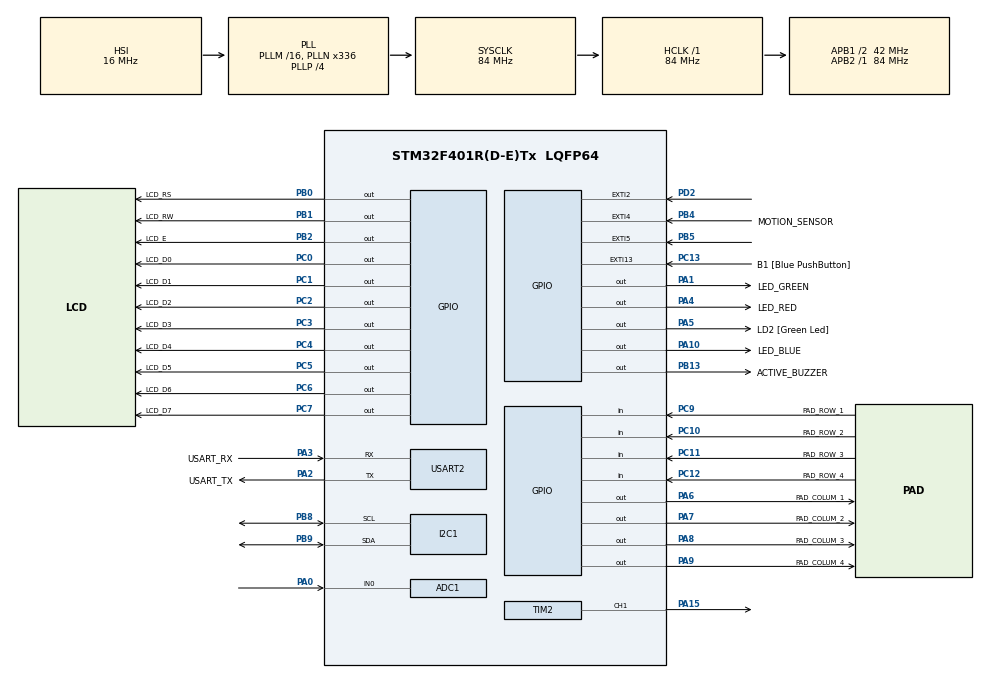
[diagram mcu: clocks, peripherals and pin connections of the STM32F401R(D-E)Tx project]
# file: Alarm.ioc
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ADC1.Channel-0\#ChannelRegularConversion=ADC_CHANNEL_0
ADC1.ClockPrescaler=ADC_CLOCK_SYNC_PCLK_DIV8
ADC1.NbrOfConversionFlag=1
ADC1.Rank-0\#ChannelRegularConversion=1
ADC1.SamplingTime-0\#ChannelRegularConversion=ADC_SAMPLETIME_480CYCLES
ADC1.master=1
Mcu.Family=STM32F4
Mcu.Name=STM32F401R(D-E)Tx
Mcu.Package=LQFP64
NVIC.EXTI2_IRQn=true\:2\:0\:true\:false\:true\:true
NVIC.EXTI4_IRQn=true\:2\:0\:true\:false\:true\:true
NVIC.EXTI9_5_IRQn=true\:2\:0\:true\:false\:true\:true
NVIC.PriorityGroup=NVIC_PRIORITYGROUP_4
NVIC.TIM1_BRK_TIM9_IRQn=true\:0\:0\:false\:false\:true\:true
NVIC.TIM1_TRG_COM_TIM11_IRQn=true\:0\:0\:false\:false\:true\:true
NVIC.TIM1_UP_TIM10_IRQn=true\:0\:0\:false\:false\:true\:true
PA0-WKUP.Signal=ADCx_IN0
PA1.GPIO_Label=LED_GREEN
PA1.GPIO_ModeDefaultOutputPP=GPIO_MODE_OUTPUT_OD
PA1.Signal=GPIO_Output
PA10.GPIO_Label=LED_BLUE
PA10.GPIO_ModeDefaultOutputPP=GPIO_MODE_OUTPUT_OD
PA10.Signal=GPIO_Output
PA13.GPIO_Label=TMS
PA13.Mode=Serial_Wire
PA13.Signal=SYS_JTMS-SWDIO
PA14.GPIO_Label=TCK
PA14.Mode=Serial_Wire
PA14.Signal=SYS_JTCK-SWCLK
PA15.Signal=S_TIM2_CH1_ETR
PA2.GPIO_Label=USART_TX
PA2.GPIO_Mode=GPIO_MODE_AF_PP
PA2.GPIO_PuPd=GPIO_NOPULL
PA2.GPIO_Speed=GPIO_SPEED_FREQ_LOW
PA2.Mode=Asynchronous
PA2.Signal=USART2_TX
PA3.GPIO_Label=USART_RX
PA3.GPIO_Mode=GPIO_MODE_AF_PP
PA3.GPIO_PuPd=GPIO_NOPULL
PA3.GPIO_Speed=GPIO_SPEED_FREQ_LOW
PA3.Mode=Asynchronous
PA3.Signal=USART2_RX
PA4.GPIO_Label=LED_RED
PA4.GPIO_ModeDefaultOutputPP=GPIO_MODE_OUTPUT_OD
PA4.Signal=GPIO_Output
PA5.GPIO_Label=LD2 [Green Led]
PA5.GPIO_Mode=GPIO_MODE_OUTPUT_PP
PA5.GPIO_PuPd=GPIO_NOPULL
PA5.GPIO_Speed=GPIO_SPEED_FREQ_LOW
PA5.Signal=GPIO_Output
PA6.GPIO_Label=PAD_COLUM_1
PA6.GPIO_ModeDefaultOutputPP=GPIO_MODE_OUTPUT_OD
PA6.GPIO_PuPd=GPIO_PULLUP
PA6.GPIO_Speed=GPIO_SPEED_FREQ_MEDIUM
PA6.Signal=GPIO_Output
PA7.GPIO_Label=PAD_COLUM_2
PA7.GPIO_ModeDefaultOutputPP=GPIO_MODE_OUTPUT_OD
PA7.GPIO_PuPd=GPIO_PULLUP
PA7.GPIO_Speed=GPIO_SPEED_FREQ_MEDIUM
PA7.Signal=GPIO_Output
PA8.GPIO_Label=PAD_COLUM_3
PA8.GPIO_ModeDefaultOutputPP=GPIO_MODE_OUTPUT_OD
PA8.GPIO_PuPd=GPIO_PULLUP
PA8.GPIO_Speed=GPIO_SPEED_FREQ_MEDIUM
PA8.Signal=GPIO_Output
PA9.GPIO_Label=PAD_COLUM_4
PA9.GPIO_ModeDefaultOutputPP=GPIO_MODE_OUTPUT_OD
PA9.GPIO_PuPd=GPIO_PULLUP
PA9.GPIO_Speed=GPIO_SPEED_FREQ_MEDIUM
PA9.Signal=GPIO_Output
PB0.GPIO_Label=LCD_RS
PB0.Signal=GPIO_Output
PB1.GPIO_Label=LCD_RW
PB1.Signal=GPIO_Output
PB13.GPIO_Label=ACTIVE_BUZZER
PB13.Signal=GPIO_Output
PB2.GPIO_Label=LCD_E
PB2.Signal=GPIO_Output
PB3.GPIO_Label=SWO
PB3.Signal=SYS_JTDO-SWO
PB4.GPIO_Label=MOTION_SENSOR
PB4.Signal=GPXTI4
PB5.GPIO_ModeDefaultEXTI=GPIO_MODE_IT_FALLING
PB5.Signal=GPXTI5
PB8.Mode=I2C
PB8.Signal=I2C1_SCL
PB9.Mode=I2C
PB9.Signal=I2C1_SDA
PC0.GPIO_Label=LCD_D0
PC0.Signal=GPIO_Output
PC1.GPIO_Label=LCD_D1
PC1.Signal=GPIO_Output
PC10.GPIO_Label=PAD_ROW_2
PC10.GPIO_PuPd=GPIO_PULLUP
PC10.Signal=GPIO_Input
PC11.GPIO_Label=PAD_ROW_3
PC11.GPIO_PuPd=GPIO_PULLUP
PC11.Signal=GPIO_Input
PC12.GPIO_Label=PAD_ROW_4
PC12.GPIO_PuPd=GPIO_PULLUP
PC12.Signal=GPIO_Input
PC13-ANTI_TAMP.GPIO_Label=B1 [Blue PushButton]
PC13-ANTI_TAMP.GPIO_ModeDefaultEXTI=GPIO_MODE_IT_FALLING
PC13-ANTI_TAMP.GPIO_PuPd=GPIO_NOPULL
PC13-ANTI_TAMP.Signal=GPXTI13
PC14-OSC32_IN.Signal=RCC_OSC32_IN
PC15-OSC32_OUT.Signal=RCC_OSC32_OUT
PC2.GPIO_Label=LCD_D2
PC2.Signal=GPIO_Output
PC3.GPIO_Label=LCD_D3
PC3.Signal=GPIO_Output
PC4.GPIO_Label=LCD_D4
PC4.Signal=GPIO_Output
PC5.GPIO_Label=LCD_D5
PC5.Signal=GPIO_Output
PC6.GPIO_Label=LCD_D6
PC6.Signal=GPIO_Output
PC7.GPIO_Label=LCD_D7
PC7.Signal=GPIO_Output
PC9.GPIO_Label=PAD_ROW_1
PC9.GPIO_PuPd=GPIO_PULLUP
PC9.Signal=GPIO_Input
PD2.Signal=GPXTI2
ProjectManager.HeapSize=0x200
ProjectManager.StackSize=0x400
ProjectManager.TargetToolchain=TrueSTUDIO
RCC.48MHZClocksFreq_Value=48000000
RCC.AHBFreq_Value=84000000
RCC.APB1CLKDivider=RCC_HCLK_DIV2
RCC.APB1Freq_Value=42000000
RCC.APB1TimFreq_Value=84000000
RCC.APB2Freq_Value=84000000
RCC.APB2TimFreq_Value=84000000
RCC.CortexFreq_Value=84000000
RCC.HCLKFreq_Value=84000000
RCC.HSE_VALUE=8000000
RCC.HSI_VALUE=16000000
RCC.LSE_VALUE=0.032768
RCC.PLLN=336
RCC.PLLP=RCC_PLLP_DIV4
RCC.PLLQ=7
RCC.SYSCLKFreq_VALUE=84000000
RCC.SYSCLKSource=RCC_SYSCLKSOURCE_PLLCLK
RCC.VCOOutputFreq_Value=336000000
SH.ADCx_IN0.0=ADC1_IN0,IN0
SH.S_TIM2_CH1_ETR.0=TIM2_CH1,PWM Generation1 CH1
TIM10.Period=62499
TIM10.Prescaler=1343
TIM11.Period=83
TIM2.Channel-PWM\ Generation1\ CH1=TIM_CHANNEL_1
TIM2.Period=64615
TIM2.Prescaler=25
TIM9.Period=63
TIM9.Prescaler=1334
USART2.VirtualMode=VM_ASYNC
VP_TIM10_VS_ClockSourceINT.Mode=Enable_Timer
VP_TIM11_VS_ClockSourceINT.Mode=Enable_Timer
VP_TIM2_VS_ClockSourceINT.Mode=Internal
VP_TIM9_VS_ClockSourceINT.Mode=Internal
board=NUCLEO-F401RE

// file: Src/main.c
/**
  ******************************************************************************
  * @file           : main.c
  * @brief          : Main program body
  ******************************************************************************
  ** This notice applies to any and all portions of this file
  * that are not between comment pairs USER CODE BEGIN and
  * USER CODE END. Other portions of this file, whether
  * inserted by the user or by software development tools
  * are owned by their respective copyright owners.
  *
  * COPYRIGHT(c) 2018 STMicroelectronics
  *
  * Redistribution and use in source and binary forms, with or without modification,
  * are permitted provided that the following conditions are met:
  *   1. Redistributions of source code must retain the above copyright notice,
  *      this list of conditions and the following disclaimer.
  *   2. Redistributions in binary form must reproduce the above copyright notice,
  *      this list of conditions and the following disclaimer in the documentation
  *      and/or other materials provided with the distribution.
  *   3. Neither the name of STMicroelectronics nor the names of its contributors
  *      may be used to endorse or promote products derived from this software
  *      without specific prior written permission.
  *
  * THIS SOFTWARE IS PROVIDED BY THE COPYRIGHT HOLDERS AND CONTRIBUTORS "AS IS"
  * AND ANY EXPRESS OR IMPLIED WARRANTIES, INCLUDING, BUT NOT LIMITED TO, THE
  * IMPLIED WARRANTIES OF MERCHANTABILITY AND FITNESS FOR A PARTICULAR PURPOSE ARE
  * DISCLAIMED. IN NO EVENT SHALL THE COPYRIGHT HOLDER OR CONTRIBUTORS BE LIABLE
  * FOR ANY DIRECT, INDIRECT, INCIDENTAL, SPECIAL, EXEMPLARY, OR CONSEQUENTIAL
  * DAMAGES (INCLUDING, BUT NOT LIMITED TO, PROCUREMENT OF SUBSTITUTE GOODS OR
  * SERVICES; LOSS OF USE, DATA, OR PROFITS; OR BUSINESS INTERRUPTION) HOWEVER
  * CAUSED AND ON ANY THEORY OF LIABILITY, WHETHER IN CONTRACT, STRICT LIABILITY,
  * OR TORT (INCLUDING NEGLIGENCE OR OTHERWISE) ARISING IN ANY WAY OUT OF THE USE
  * OF THIS SOFTWARE, EVEN IF ADVISED OF THE POSSIBILITY OF SUCH DAMAGE.
  *
  ******************************************************************************
  */
#include "main.h"
#include "stm32f4xx_hal.h"

/* USER CODE BEGIN Includes */
#include "Alarm.h"

/* USER CODE END Includes */

ADC_HandleTypeDef hadc1;

I2C_HandleTypeDef hi2c1;

TIM_HandleTypeDef htim2;
TIM_HandleTypeDef htim9;
TIM_HandleTypeDef htim10;
TIM_HandleTypeDef htim11;

UART_HandleTypeDef huart2;

/* USER CODE BEGIN PV */
/* Private variables ---------------------------------------------------------*/

/* USER CODE END PV */

void SystemClock_Config(void);
static void MX_GPIO_Init(void);
static void MX_USART2_UART_Init(void);
static void MX_TIM10_Init(void);
static void MX_TIM11_Init(void);
static void MX_I2C1_Init(void);
static void MX_ADC1_Init(void);
static void MX_TIM2_Init(void);
static void MX_TIM9_Init(void);

void HAL_TIM_MspPostInit(TIM_HandleTypeDef *htim);

/* USER CODE BEGIN PFP */
/* Private function prototypes -----------------------------------------------*/

/* USER CODE END PFP */

int main(void)
{

  /* MCU Configuration----------------------------------------------------------*/

  /* Reset of all peripherals, Initializes the Flash interface and the Systick. */
  HAL_Init();

  /* Configure the system clock */
  SystemClock_Config();

  /* Initialize all configured peripherals */
  MX_GPIO_Init();
  MX_USART2_UART_Init();
  MX_TIM10_Init();
  MX_TIM11_Init();
  MX_I2C1_Init();
  MX_ADC1_Init();
  MX_TIM2_Init();
  MX_TIM9_Init();

  /* Infinite loop */
  /* USER CODE BEGIN WHILE */
  while (1){
	  Alarm_status();

  /* USER CODE END WHILE */

  }

}

void SystemClock_Config(void)
{

  RCC_OscInitTypeDef RCC_OscInitStruct;
  RCC_ClkInitTypeDef RCC_ClkInitStruct;

    /**Configure the main internal regulator output voltage
    */
  __HAL_RCC_PWR_CLK_ENABLE();

  __HAL_PWR_VOLTAGESCALING_CONFIG(PWR_REGULATOR_VOLTAGE_SCALE2);

    /**Initializes the CPU, AHB and APB busses clocks
    */
  RCC_OscInitStruct.OscillatorType = RCC_OSCILLATORTYPE_HSI;
  RCC_OscInitStruct.HSIState = RCC_HSI_ON;
  RCC_OscInitStruct.HSICalibrationValue = 16;
  RCC_OscInitStruct.PLL.PLLState = RCC_PLL_ON;
  RCC_OscInitStruct.PLL.PLLSource = RCC_PLLSOURCE_HSI;
  RCC_OscInitStruct.PLL.PLLM = 16;
  RCC_OscInitStruct.PLL.PLLN = 336;
  RCC_OscInitStruct.PLL.PLLP = RCC_PLLP_DIV4;
  RCC_OscInitStruct.PLL.PLLQ = 7;
  if (HAL_RCC_OscConfig(&RCC_OscInitStruct) != HAL_OK)
  {
    _Error_Handler(__FILE__, __LINE__);
  }

    /**Initializes the CPU, AHB and APB busses clocks
    */
  RCC_ClkInitStruct.ClockType = RCC_CLOCKTYPE_HCLK|RCC_CLOCKTYPE_SYSCLK
                              |RCC_CLOCKTYPE_PCLK1|RCC_CLOCKTYPE_PCLK2;
  RCC_ClkInitStruct.SYSCLKSource = RCC_SYSCLKSOURCE_PLLCLK;
  RCC_ClkInitStruct.AHBCLKDivider = RCC_SYSCLK_DIV1;
  RCC_ClkInitStruct.APB1CLKDivider = RCC_HCLK_DIV2;
  RCC_ClkInitStruct.APB2CLKDivider = RCC_HCLK_DIV1;

  if (HAL_RCC_ClockConfig(&RCC_ClkInitStruct, FLASH_LATENCY_2) != HAL_OK)
  {
    _Error_Handler(__FILE__, __LINE__);
  }

    /**Configure the Systick interrupt time
    */
  HAL_SYSTICK_Config(HAL_RCC_GetHCLKFreq()/1000);

    /**Configure the Systick
    */
  HAL_SYSTICK_CLKSourceConfig(SYSTICK_CLKSOURCE_HCLK);

  /* SysTick_IRQn interrupt configuration */
  HAL_NVIC_SetPriority(SysTick_IRQn, 0, 0);
}

/* ADC1 init function */
static void MX_ADC1_Init(void)
{

  ADC_ChannelConfTypeDef sConfig;

    /**Configure the global features of the ADC (Clock, Resolution, Data Alignment and number of conversion)
    */
  hadc1.Instance = ADC1;
  hadc1.Init.ClockPrescaler = ADC_CLOCK_SYNC_PCLK_DIV8;
  hadc1.Init.Resolution = ADC_RESOLUTION_12B;
  hadc1.Init.ScanConvMode = DISABLE;
  hadc1.Init.ContinuousConvMode = DISABLE;
  hadc1.Init.DiscontinuousConvMode = DISABLE;
  hadc1.Init.ExternalTrigConvEdge = ADC_EXTERNALTRIGCONVEDGE_NONE;
  hadc1.Init.ExternalTrigConv = ADC_SOFTWARE_START;
  hadc1.Init.DataAlign = ADC_DATAALIGN_RIGHT;
  hadc1.Init.NbrOfConversion = 1;
  hadc1.Init.DMAContinuousRequests = DISABLE;
  hadc1.Init.EOCSelection = ADC_EOC_SINGLE_CONV;
  if (HAL_ADC_Init(&hadc1) != HAL_OK)
  {
    _Error_Handler(__FILE__, __LINE__);
  }

    /**Configure for the selected ADC regular channel its corresponding rank in the sequencer and its sample time.
    */
  sConfig.Channel = ADC_CHANNEL_0;
  sConfig.Rank = 1;
  sConfig.SamplingTime = ADC_SAMPLETIME_480CYCLES;
  if (HAL_ADC_ConfigChannel(&hadc1, &sConfig) != HAL_OK)
  {
    _Error_Handler(__FILE__, __LINE__);
  }

}

/* I2C1 init function */
static void MX_I2C1_Init(void)
{

  hi2c1.Instance = I2C1;
  hi2c1.Init.ClockSpeed = 100000;
  hi2c1.Init.DutyCycle = I2C_DUTYCYCLE_2;
  hi2c1.Init.OwnAddress1 = 0;
  hi2c1.Init.AddressingMode = I2C_ADDRESSINGMODE_7BIT;
  hi2c1.Init.DualAddressMode = I2C_DUALADDRESS_DISABLE;
  hi2c1.Init.OwnAddress2 = 0;
  hi2c1.Init.GeneralCallMode = I2C_GENERALCALL_DISABLE;
  hi2c1.Init.NoStretchMode = I2C_NOSTRETCH_DISABLE;
  if (HAL_I2C_Init(&hi2c1) != HAL_OK)
  {
    _Error_Handler(__FILE__, __LINE__);
  }

}

/* TIM2 init function */
static void MX_TIM2_Init(void)
{

  TIM_ClockConfigTypeDef sClockSourceConfig;
  TIM_MasterConfigTypeDef sMasterConfig;
  TIM_OC_InitTypeDef sConfigOC;

  htim2.Instance = TIM2;
  htim2.Init.Prescaler = 25;
  htim2.Init.CounterMode = TIM_COUNTERMODE_UP;
  htim2.Init.Period = 64615;
  htim2.Init.ClockDivision = TIM_CLOCKDIVISION_DIV1;
  if (HAL_TIM_Base_Init(&htim2) != HAL_OK)
  {
    _Error_Handler(__FILE__, __LINE__);
  }

  sClockSourceConfig.ClockSource = TIM_CLOCKSOURCE_INTERNAL;
  if (HAL_TIM_ConfigClockSource(&htim2, &sClockSourceConfig) != HAL_OK)
  {
    _Error_Handler(__FILE__, __LINE__);
  }

  if (HAL_TIM_PWM_Init(&htim2) != HAL_OK)
  {
    _Error_Handler(__FILE__, __LINE__);
  }

  sMasterConfig.MasterOutputTrigger = TIM_TRGO_RESET;
  sMasterConfig.MasterSlaveMode = TIM_MASTERSLAVEMODE_DISABLE;
  if (HAL_TIMEx_MasterConfigSynchronization(&htim2, &sMasterConfig) != HAL_OK)
  {
    _Error_Handler(__FILE__, __LINE__);
  }

  sConfigOC.OCMode = TIM_OCMODE_PWM1;
  sConfigOC.Pulse = 0;
  sConfigOC.OCPolarity = TIM_OCPOLARITY_HIGH;
  sConfigOC.OCFastMode = TIM_OCFAST_DISABLE;
  if (HAL_TIM_PWM_ConfigChannel(&htim2, &sConfigOC, TIM_CHANNEL_1) != HAL_OK)
  {
    _Error_Handler(__FILE__, __LINE__);
  }

  HAL_TIM_MspPostInit(&htim2);

}

/* TIM9 init function */
static void MX_TIM9_Init(void)
{

  TIM_ClockConfigTypeDef sClockSourceConfig;

  htim9.Instance = TIM9;
  htim9.Init.Prescaler = 1334;
  htim9.Init.CounterMode = TIM_COUNTERMODE_UP;
  htim9.Init.Period = 63;
  htim9.Init.ClockDivision = TIM_CLOCKDIVISION_DIV1;
  if (HAL_TIM_Base_Init(&htim9) != HAL_OK)
  {
    _Error_Handler(__FILE__, __LINE__);
  }

  sClockSourceConfig.ClockSource = TIM_CLOCKSOURCE_INTERNAL;
  if (HAL_TIM_ConfigClockSource(&htim9, &sClockSourceConfig) != HAL_OK)
  {
    _Error_Handler(__FILE__, __LINE__);
  }

}

/* TIM10 init function */
static void MX_TIM10_Init(void)
{

  htim10.Instance = TIM10;
  htim10.Init.Prescaler = 1343;
  htim10.Init.CounterMode = TIM_COUNTERMODE_UP;
  htim10.Init.Period = 62499;
  htim10.Init.ClockDivision = TIM_CLOCKDIVISION_DIV1;
  if (HAL_TIM_Base_Init(&htim10) != HAL_OK)
  {
    _Error_Handler(__FILE__, __LINE__);
  }

}

/* TIM11 init function */
static void MX_TIM11_Init(void)
{

  htim11.Instance = TIM11;
  htim11.Init.Prescaler = 0;
  htim11.Init.CounterMode = TIM_COUNTERMODE_UP;
  htim11.Init.Period = 83;
  htim11.Init.ClockDivision = TIM_CLOCKDIVISION_DIV1;
  if (HAL_TIM_Base_Init(&htim11) != HAL_OK)
  {
    _Error_Handler(__FILE__, __LINE__);
  }

}

/* USART2 init function */
static void MX_USART2_UART_Init(void)
{

  huart2.Instance = USART2;
  huart2.Init.BaudRate = 115200;
  huart2.Init.WordLength = UART_WORDLENGTH_8B;
  huart2.Init.StopBits = UART_STOPBITS_1;
  huart2.Init.Parity = UART_PARITY_NONE;
  huart2.Init.Mode = UART_MODE_TX_RX;
  huart2.Init.HwFlowCtl = UART_HWCONTROL_NONE;
  huart2.Init.OverSampling = UART_OVERSAMPLING_16;
  if (HAL_UART_Init(&huart2) != HAL_OK)
  {
    _Error_Handler(__FILE__, __LINE__);
  }

}

/** Configure pins as
        * Analog
        * Input
        * Output
        * EVENT_OUT
        * EXTI
*/
static void MX_GPIO_Init(void)
{

  GPIO_InitTypeDef GPIO_InitStruct;

  /* GPIO Ports Clock Enable */
  __HAL_RCC_GPIOC_CLK_ENABLE();
  __HAL_RCC_GPIOA_CLK_ENABLE();
  __HAL_RCC_GPIOB_CLK_ENABLE();
  __HAL_RCC_GPIOD_CLK_ENABLE();

  /*Configure GPIO pin Output Level */
  HAL_GPIO_WritePin(GPIOC, LCD_D0_Pin|LCD_D1_Pin|LCD_D2_Pin|LCD_D3_Pin
                          |LCD_D4_Pin|LCD_D5_Pin|LCD_D6_Pin|LCD_D7_Pin, GPIO_PIN_RESET);

  /*Configure GPIO pin Output Level */
  HAL_GPIO_WritePin(GPIOA, LED_GREEN_Pin|LED_RED_Pin|LD2_Pin|PAD_COLUM_1_Pin
                          |PAD_COLUM_2_Pin|PAD_COLUM_3_Pin|PAD_COLUM_4_Pin|LED_BLUE_Pin, GPIO_PIN_RESET);

  /*Configure GPIO pin Output Level */
  HAL_GPIO_WritePin(GPIOB, LCD_RS_Pin|LCD_RW_Pin|LCD_E_Pin|ACTIVE_BUZZER_Pin, GPIO_PIN_RESET);

  /*Configure GPIO pin : B1_Pin */
  GPIO_InitStruct.Pin = B1_Pin;
  GPIO_InitStruct.Mode = GPIO_MODE_IT_FALLING;
  GPIO_InitStruct.Pull = GPIO_NOPULL;
  HAL_GPIO_Init(B1_GPIO_Port, &GPIO_InitStruct);

  /*Configure GPIO pins : LCD_D0_Pin LCD_D1_Pin LCD_D2_Pin LCD_D3_Pin
                           LCD_D4_Pin LCD_D5_Pin LCD_D6_Pin LCD_D7_Pin */
  GPIO_InitStruct.Pin = LCD_D0_Pin|LCD_D1_Pin|LCD_D2_Pin|LCD_D3_Pin
                          |LCD_D4_Pin|LCD_D5_Pin|LCD_D6_Pin|LCD_D7_Pin;
  GPIO_InitStruct.Mode = GPIO_MODE_OUTPUT_PP;
  GPIO_InitStruct.Pull = GPIO_NOPULL;
  GPIO_InitStruct.Speed = GPIO_SPEED_FREQ_LOW;
  HAL_GPIO_Init(GPIOC, &GPIO_InitStruct);

  /*Configure GPIO pins : LED_GREEN_Pin LED_RED_Pin LED_BLUE_Pin */
  GPIO_InitStruct.Pin = LED_GREEN_Pin|LED_RED_Pin|LED_BLUE_Pin;
  GPIO_InitStruct.Mode = GPIO_MODE_OUTPUT_OD;
  GPIO_InitStruct.Pull = GPIO_NOPULL;
  GPIO_InitStruct.Speed = GPIO_SPEED_FREQ_LOW;
  HAL_GPIO_Init(GPIOA, &GPIO_InitStruct);

  /*Configure GPIO pin : LD2_Pin */
  GPIO_InitStruct.Pin = LD2_Pin;
  GPIO_InitStruct.Mode = GPIO_MODE_OUTPUT_PP;
  GPIO_InitStruct.Pull = GPIO_NOPULL;
  GPIO_InitStruct.Speed = GPIO_SPEED_FREQ_LOW;
  HAL_GPIO_Init(LD2_GPIO_Port, &GPIO_InitStruct);

  /*Configure GPIO pins : PAD_COLUM_1_Pin PAD_COLUM_2_Pin PAD_COLUM_3_Pin PAD_COLUM_4_Pin */
  GPIO_InitStruct.Pin = PAD_COLUM_1_Pin|PAD_COLUM_2_Pin|PAD_COLUM_3_Pin|PAD_COLUM_4_Pin;
  GPIO_InitStruct.Mode = GPIO_MODE_OUTPUT_OD;
  GPIO_InitStruct.Pull = GPIO_PULLUP;
  GPIO_InitStruct.Speed = GPIO_SPEED_FREQ_MEDIUM;
  HAL_GPIO_Init(GPIOA, &GPIO_InitStruct);

  /*Configure GPIO pins : LCD_RS_Pin LCD_RW_Pin LCD_E_Pin ACTIVE_BUZZER_Pin */
  GPIO_InitStruct.Pin = LCD_RS_Pin|LCD_RW_Pin|LCD_E_Pin|ACTIVE_BUZZER_Pin;
  GPIO_InitStruct.Mode = GPIO_MODE_OUTPUT_PP;
  GPIO_InitStruct.Pull = GPIO_NOPULL;
  GPIO_InitStruct.Speed = GPIO_SPEED_FREQ_LOW;
  HAL_GPIO_Init(GPIOB, &GPIO_InitStruct);

  /*Configure GPIO pins : PAD_ROW_1_Pin PAD_ROW_2_Pin PAD_ROW_3_Pin PAD_ROW_4_Pin */
  GPIO_InitStruct.Pin = PAD_ROW_1_Pin|PAD_ROW_2_Pin|PAD_ROW_3_Pin|PAD_ROW_4_Pin;
  GPIO_InitStruct.Mode = GPIO_MODE_INPUT;
  GPIO_InitStruct.Pull = GPIO_PULLUP;
  HAL_GPIO_Init(GPIOC, &GPIO_InitStruct);

  /*Configure GPIO pin : PD2 */
  GPIO_InitStruct.Pin = GPIO_PIN_2;
  GPIO_InitStruct.Mode = GPIO_MODE_IT_RISING;
  GPIO_InitStruct.Pull = GPIO_NOPULL;
  HAL_GPIO_Init(GPIOD, &GPIO_InitStruct);

  /*Configure GPIO pin : MOTION_SENSOR_Pin */
  GPIO_InitStruct.Pin = MOTION_SENSOR_Pin;
  GPIO_InitStruct.Mode = GPIO_MODE_IT_RISING;
  GPIO_InitStruct.Pull = GPIO_NOPULL;
  HAL_GPIO_Init(MOTION_SENSOR_GPIO_Port, &GPIO_InitStruct);

  /*Configure GPIO pin : PB5 */
  GPIO_InitStruct.Pin = GPIO_PIN_5;
  GPIO_InitStruct.Mode = GPIO_MODE_IT_FALLING;
  GPIO_InitStruct.Pull = GPIO_NOPULL;
  HAL_GPIO_Init(GPIOB, &GPIO_InitStruct);

  /* EXTI interrupt init*/
  HAL_NVIC_SetPriority(EXTI2_IRQn, 2, 0);
  HAL_NVIC_EnableIRQ(EXTI2_IRQn);

  HAL_NVIC_SetPriority(EXTI4_IRQn, 2, 0);
  HAL_NVIC_EnableIRQ(EXTI4_IRQn);

  HAL_NVIC_SetPriority(EXTI9_5_IRQn, 2, 0);
  HAL_NVIC_EnableIRQ(EXTI9_5_IRQn);

}

void _Error_Handler(char *file, int line)
{
  while(1)
  {
  }
}

/************************ (C) COPYRIGHT STMicroelectronics *****END OF FILE****/
